# NM1500_v1 register map
File version: 1.0
Registers are 32-bit, read-write, reset 0x0 unless marked. A register's access mark holds for its fields unless they carry their own. Offsets are from the block's base; [hi:lo] are bit positions; {n}, {i} and the like mark numbered series; 'fields as' and 'values as' point back to an identical list.

## GPIOB — GPIO Register Map
Base 0x50004300
{0x0+0x20*i} P{i}_0 (reset mask 0xFFFFFFF0) (i=0..10) — GPIO Port n bit m I/O value
  [0] Pnm — Port n bit m (Pnm) value. Write: For example: a writing of P00 reflects the value of bit P0_DOUT[0], a reading returns the value of P0_PIN[0]. Note: The write operation will not be affected by register GPIOx_DMASK
    0=Clear Pnm latch to output low. Port pin of Pnm is a low level; 1=Set Pnm latch to output high. Port pin of Pnm is a high level
{0x4+0x20*i} P{i}_1 (reset mask 0xFFFFFFF0) (i=0..10) — GPIO Port n bit m I/O value
  fields as P0_0
{0x8+0x20*i} P{i}_2 (reset mask 0xFFFFFFF0) (i=0..10) — GPIO Port n bit m I/O value
  fields as P0_0
{0xC+0x20*i} P{i}_3 (reset mask 0xFFFFFFF0) (i=0..10) — GPIO Port n bit m I/O value
  fields as P0_0
{0x10+0x20*i} P{i}_4 (reset mask 0xFFFFFFF0) (i=0..10) — GPIO Port n bit m I/O value
  fields as P0_0
{0x14+0x20*i} P{i}_5 (reset mask 0xFFFFFFF0) (i=0..10) — GPIO Port n bit m I/O value
  fields as P0_0
{0x18+0x20*i} P{i}_6 (reset mask 0xFFFFFFF0) (i=0..10) — GPIO Port n bit m I/O value
  fields as P0_0
{0x1C+0x20*i} P{i}_7 (reset mask 0xFFFFFFF0) (i=0..10) — GPIO Port n bit m I/O value
  fields as P0_0

## WWDT — WWDT Register Map
Base 0x40004100
0x00 WWDTRLD wo — Window Watchdog Timer Reload Counter Register
  [31:0] WWDTRLD — WWDT Reload Counter Register. Writing 0x00005AA5 to this register will reload the Window Watchdog Timer counter value to 0x3F. Note: Software can only write WWDTRLD to reload WWDT counter value when current WWDT counter value between 0 and WINCMP. If software writes WWDTRLD when current WWDT counter value larger than WINCMP, WWDT reset signal will generate immediately.
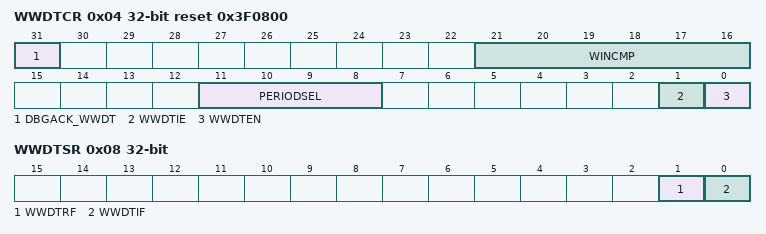
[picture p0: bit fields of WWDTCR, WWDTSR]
0x04 WWDTCR reset 0x3F0800 — Window Watchdog Timer Control Register
  [31] DBGACK_WWDT — ICE debug mode acknowledge Disable
    0=WWDT counter stopped if system is in Debug mode; 1=WWDT still counted even system is in Debug mode
  [21:16] WINCMP — WWDT Window Compare Register. Set this register to adjust the valid reload window. Note: Software can only write WWDTRLD to reload WWDT counter value when current WWDT counter value between 0 and WINCMP. If Software writes WWDTRLD when current WWDT counter value larger than WINCMP, WWDT reset signal will generate immediately.
  [11:8] PERIODSEL — WWDT Pre-scale Period Select
  [1] WWDTIE — WWDT Interrupt Enable. Setting this bit to enable the Window Watchdog Timer time-out interrupt function.
    0=WWDT time-out interrupt function Disabled if WWDTIF (WWDTSR[0] WWDT compare match interrupt flag) is 1; 1=WWDT time-out interrupt function Enabled if WWDTIF (WWDTSR[0] WWDT compare match interrupt flag) is 1
  [0] WWDTEN — WWDT Enable. Set this bit to enable Window Watchdog Timer counter counting.
    0=Window Watchdog Timer counter is stopped; 1=Window Watchdog Timer counter is starting counting
0x08 WWDTSR — Window Watchdog Timer Status Register
  [1] WWDTRF — WWDT Reset Flag. When WWDT counter counts down to 0 or writes WWDTRLD during current WWDT counter value larger than WINCMP, chip will be reset and this bit is set to 1. This bit will be cleared to 0 by writing 1 to itself.
  [0] WWDTIF — WWDT Compare Match Interrupt Flag. When current WWDT counter value matches to WWCMP, this bit is set to 1. This bit will be cleared by writing 1 to itself.
0x0C WWDTCVR ro reset 0x3F — Window Watchdog Timer Counter Value Register
  [5:0] WWDTCVAL — WWDT Counter Value. This register reflects the current WWDT counter value and this register is read only

## MDUG — MDU Register Map
Base 0x401D0800
0x00 MDUSCON — MDU Switch Control
  [0] MDUS — MDU Switch Control Register
    0=MDU is controlled by MDU0 control register; 1=MDU is controlled by MDU1 control register
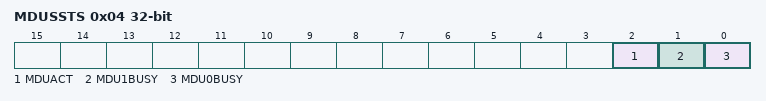
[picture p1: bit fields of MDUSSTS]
0x04 MDUSSTS — MDU Switch Status
  [2] MDUACT — MDU Active Set
    0=MDU0 is active; 1=MDU1 is active
  [1] MDU1BUSY
    0=MDU1 is idle; 1=MDU1 is busy
  [0] MDU0BUSY
    0=MDU0 is idle; 1=MDU0 is busy
